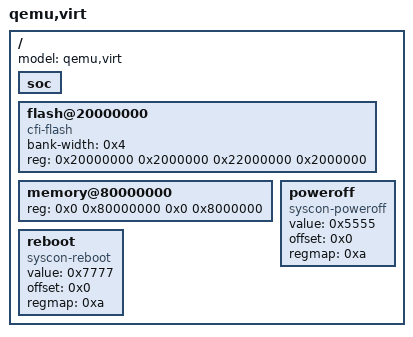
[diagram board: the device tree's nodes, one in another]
/dts-v1/;

/include/ "generic.dtsi"

/ {
    #address-cells = <0x2>;
    #size-cells = <0x2>;
    model = "qemu,virt";
    soc {
        // TODO
    };
    flash@20000000 {
        bank-width = <0x4>;
        reg = <0x20000000 0x2000000 0x22000000 0x2000000>;
        compatible = "cfi-flash";
    };
    memory@80000000 {
        device_type = "memory";
        reg = <0x0 0x80000000 0x0 0x8000000>;
    };
    poweroff {
        value = <0x5555>;
        offset = <0x0>;
        regmap = <0xa>;
        compatible = "syscon-poweroff";
    };
    reboot {
        value = <0x7777>;
        offset = <0x0>;
        regmap = <0xa>;
        compatible = "syscon-reboot";
    };
};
